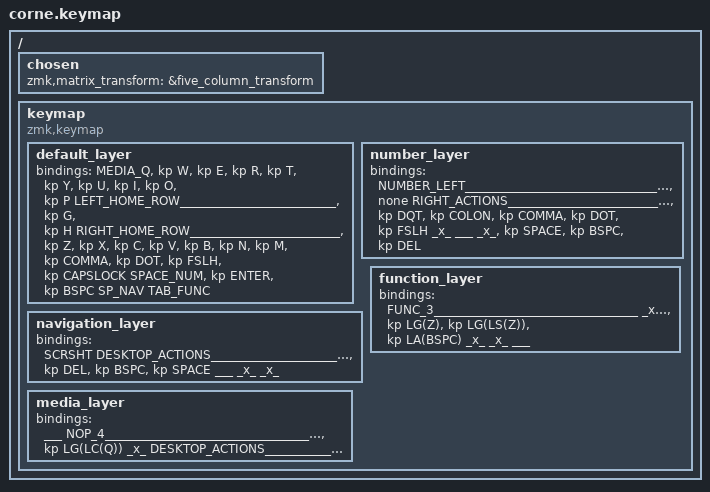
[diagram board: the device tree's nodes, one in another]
#include <behaviors.dtsi>
#include <dt-bindings/zmk/keys.h>
#include <dt-bindings/zmk/bt.h>
#include <dt-bindings/zmk/outputs.h>

// layers
#define DEF     0
#define NUM     1
#define NAV     2
#define MEDIA   3
#define FUN     4

#include "keys/36.h"
#include "includes/macros.dtsi"
#include "includes/combos.dtsi"
#include "includes/behaviors.dtsi"





// Layers toggles         hold     tap
#define MEDIA_L    &ltr   MEDIA    LG(C)
#define MEDIA_R    &ltr   MEDIA    LBKT
#define SP_NAV     &ltr   NAV      SPACE
#define TAB_FUNC   &ltr  FUN       TAB  
#define SPACE_NUM  &ltr  NUM       SPACE  
#define MEDIA_Q    &ltr MEDIA  Q


// shorter codes
#define SCRSHT   &kp  LS(LG(N1))
#define OUTTOG   &out OUT_TOG // toggle keyboard output bluetooth/usb
#define ___      &trans      //  transparent 
#define _x_      &none
#define SUPER    &ltsk NAV LS(LG(LC(LALT)))

// Home row mods
#define HRML(k1, k2, k3, k4) &hml LCTRL  k1  &hml LALT  k2 &hml LGUI k3 &hml LSHFT k4
#define HRMR(k1, k2, k3, k4) &hmr RSHFT k1  &hmr RGUI k2 &hmr RALT  k3 &hmr RCTRL  k4

// 5 Rows
#define NUMBER_TOP_ROW___________________________________  &kp N5    &kp N6    &kp N7    &kp N8    &kp N9   
#define NUMBER_BOTTOM_ROW________________________________  &kp N1    &kp N2    &kp N3    &kp N4    &kp N0
#define NOP______________________________________________  &none     &none     &none     &none     &none  
#define PAGE_CONTROL_ROW_________________________________  &kp HOME  &kp PG_DN &kp PG_UP  &kp END  &kp INS    
#define BLUETOOTH________________________________________  &bt BT_PRV  &bt BT_NXT  &out OUT_USB  &out OUT_BLE  &bt BT_CLR_ALL 
#define BLUETOOTH_TOP____________________________________  &bt BT_SEL 1  &bt BT_SEL 2    &bt BT_SEL 3   &bt BT_SEL 4 &bt BT_SEL 0
#define MOVE_MAC_OS______________________________________  &kp LC(LEFT) &kp LC(DOWN) &kp LC(UP) &kp LC(RIGHT)  &none  


// 4 Rows
#define NAVIGATION_____________________________            &kp LEFT     &kp DOWN       &kp UP           &kp RIGHT  
#define LEFT_ACTIONS___________________________            &kp LGUI     &kp LALT       &kp LCTRL        &kp LSHFT 
#define RIGHT_ACTIONS__________________________            &kp RSHFT    &kp RCTRL      &kp RALT         &kp RGUI
#define DESKTOP_ACTIONS________________________            &kp  LC(UP)  &kp  LC(LEFT)  &kp  LC(RIGHT)   &kp LG(SPACE)
#define LEFT_HOME_ROW__________________________            HRML(A,        S,        D,        F)
#define RIGHT_HOME_ROW_________________________            HRMR(J,        K,        L,       SEMI)
#define NOP_4__________________________________            &none         &none       &none       &none

// Function rows
#define FUNC_1__________________________________            &kp F1    &kp F2    &kp F3  &kp F4
#define FUNC_2__________________________________            &kp F5    &kp F6    &kp F7  &kp F8
#define FUNC_3__________________________________            &kp F9    &kp F10   &kp F11 &kp F12 

// 3 Rows
#define VOLUME_CONTROL_______________                      &kp K_VOL_DN    &kp K_MUTE          &kp K_VOL_UP  
#define PLAY_CONTROL_________________                      &kp  C_PREV     &kp  C_PLAY_PAUSE   &kp  C_NEXT
//#define COPY_PASTE___________________                      &kp LG(X)       &kp LG(C)           &kp LG(V)            

// Number pad
#define NUMBER_LEFT______________________________________  &kp N1    &kp N2    &kp N3  &kp N4    &kp N5
#define NUMBER_RIGHT_____________________________________  &kp N6    &kp N7    &kp N8  &kp N9    &kp N0

#define BRIGHTNESS_________ &kp C_BRIGHTNESS_DEC  &kp C_BRIGHTNESS_INC



/ {
  chosen {
    zmk,matrix_transform = &five_column_transform;
  };
};

/ {
  keymap {
    compatible = "zmk,keymap";
    default_layer { // layer 0 (default)
      bindings = <
// ╭─────────────────────────────────────────────────╮   ╭─────────────────────────────────────────────────╮
     MEDIA_Q  &kp W     &kp E     &kp R     &kp T         &kp Y     &kp U     &kp I     &kp O     &kp P
// ├─────────┼─────────┼─────────┼─────────┼─────────┤   ├─────────┼─────────┼─────────┼─────────┼─────────┤
// │    A    │    S    │    D    │    F    │    G    │   │    H    │    J    │    K    │    L    │    '    │
    LEFT_HOME_ROW__________________________    &kp G         &kp H  RIGHT_HOME_ROW_________________________
// ├─────────┼─────────┼─────────┼─────────┼─────────┤   ├─────────┼─────────┼─────────┼─────────┼─────────┤
// │    Z    │    X    │    C    │    V    │    B    │   │    N    │    M    │    ,    │    .    │    /    │
    &kp Z     &kp X     &kp C     &kp V     &kp B         &kp N     &kp M     &kp COMMA &kp DOT  &kp FSLH
// ╰─────────┼─────────┼─────────┼─────────┼─────────┤   ├─────────┼─────────┼─────────┼─────────┼─────────╯
                    &kp CAPSLOCK  SPACE_NUM &kp ENTER     &kp BSPC  SP_NAV   TAB_FUNC 
//                     ╰─────────────────────────────╯   ╰─────────────────────────────╯
      >;
    };
    number_layer { // layer 1 (numbers)
      bindings = <
// ╭─────────────────────────────────────────────────╮   ╭─────────────────────────────────────────────────╮
    NUMBER_LEFT______________________________________     NUMBER_RIGHT_____________________________________
// ├─────────┼─────────┼─────────┼─────────┼─────────┤   ├─────────┼─────────┼─────────┼─────────┼─────────┤
    MOVE_MAC_OS______________________________________    &none    RIGHT_ACTIONS__________________________
// ├─────────┼─────────┼─────────┼─────────┼─────────┤   ├─────────┼─────────┼─────────┼─────────┼─────────┤
    NOP______________________________________________    &kp DQT   &kp COLON  &kp COMMA &kp DOT  &kp FSLH
// ╰─────────┼─────────┼─────────┼─────────┼─────────┤   ├─────────┼─────────┼─────────┼─────────┼─────────╯
                           _x_       ___       _x_       &kp SPACE  &kp BSPC  &kp DEL  
//                     ╰─────────────────────────────╯   ╰─────────────────────────────╯
      >;
    };

    navigation_layer { // layer 2 (navigation)
      bindings = <
// ╭─────────────────────────────────────────────────╮   ╭─────────────────────────────────────────────────╮
      SCRSHT  DESKTOP_ACTIONS________________________     NOP______________________________________________
// ├─────────┼─────────┼─────────┼─────────┼─────────┤   ├─────────┼─────────┼─────────┼─────────┼─────────┤
    LEFT_ACTIONS___________________________    _x_        NAVIGATION_____________________________    _x_
// ├─────────┼─────────┼─────────┼─────────┼─────────┤   ├─────────┼─────────┼─────────┼─────────┼─────────┤
    NOP______________________________________________     PAGE_CONTROL_ROW_________________________________
// ╰─────────┼─────────┼─────────┼─────────┼─────────┤   ├─────────┼─────────┼─────────┼─────────┼─────────╯
                         &kp DEL  &kp BSPC &kp SPACE         ___       _x_       _x_
//                     ╰─────────────────────────────╯   ╰─────────────────────────────╯
      >;
    };
    media_layer { // layer 3 (media)
      bindings = <
// ╭─────────────────────────────────────────────────╮   ╭─────────────────────────────────────────────────╮
       ___    NOP_4__________________________________    BRIGHTNESS_________    _x_       _x_   &kp LG(LC(Q))
// ├─────────┼─────────┼─────────┼─────────┼─────────┤   ├─────────┼─────────┼─────────┼─────────┼─────────┤
       _x_    DESKTOP_ACTIONS________________________        _x_    DESKTOP_ACTIONS________________________
// ├─────────┼─────────┼─────────┼─────────┼─────────┤   ├─────────┼─────────┼─────────┼─────────┼─────────┤
    NOP______________________________________________     NOP______________________________________________
// ╰─────────┼─────────┼─────────┼─────────┼─────────┤   ├─────────┼─────────┼─────────┼─────────┼─────────╯
                        VOLUME_CONTROL_______________     PLAY_CONTROL_________________
//                     ╰─────────────────────────────╯   ╰─────────────────────────────╯
      >;
    };
    function_layer { // layer 4 (function)
      bindings = <
// ╭─────────────────────────────────────────────────╮   ╭─────────────────────────────────────────────────╮
    FUNC_3__________________________________ _x_           BLUETOOTH_TOP____________________________________
// ├─────────┼─────────┼─────────┼─────────┼─────────┤   ├─────────┼─────────┼─────────┼─────────┼─────────┤
    FUNC_2__________________________________   _x_           _x_    RIGHT_ACTIONS__________________________
// ├─────────┼─────────┼─────────┼─────────┼─────────┤   ├─────────┼─────────┼─────────┼─────────┼─────────┤
    FUNC_1__________________________________&kp CAPSLOCK BLUETOOTH________________________________________
// ╰─────────┼─────────┼─────────┼─────────┼─────────┤   ├─────────┼─────────┼─────────┼─────────┼─────────╯
//                   Undo │  Redo  │   Remove Word   │   │    NOP  │   NOP   │   LAYER   │
               &kp LG(Z) &kp LG(LS(Z)) &kp LA(BSPC)           _x_       _x_       ___
//                     ╰─────────────────────────────╯   ╰─────────────────────────────╯
      >;
    };

  };
};

// vim:ft=cpp
